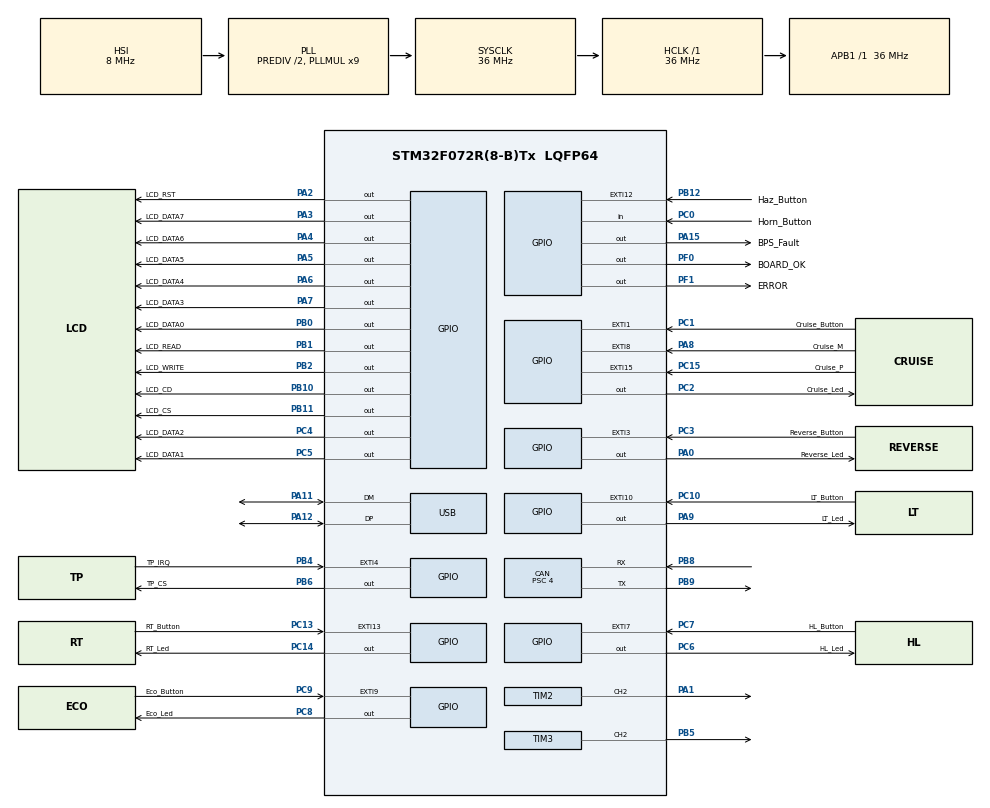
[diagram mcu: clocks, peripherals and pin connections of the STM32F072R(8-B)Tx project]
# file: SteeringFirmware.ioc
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CAN.BS1=CAN_BS1_14TQ
CAN.BS2=CAN_BS2_3TQ
CAN.CalculateBaudRate=500000
CAN.CalculateTimeBit=2000
CAN.CalculateTimeQuantum=111.11111111111111
CAN.Mode=CAN_MODE_NORMAL
CAN.Prescaler=4
CAN.TTCM=DISABLE
FREERTOS.Tasks01=defaultTask,8,128,StartDefaultTask,Default,NULL,Static,defaultTaskBuffer,defaultTaskControlBlock
FREERTOS.configCHECK_FOR_STACK_OVERFLOW=1
FREERTOS.configGENERATE_RUN_TIME_STATS=0
FREERTOS.configTIMER_TASK_PRIORITY=24
FREERTOS.configTIMER_TASK_STACK_DEPTH=256
FREERTOS.configTOTAL_HEAP_SIZE=3072
FREERTOS.configUSE_NEWLIB_REENTRANT=1
Mcu.Family=STM32F0
Mcu.Name=STM32F072R(8-B)Tx
Mcu.Package=LQFP64
NVIC.CEC_CAN_IRQn=true\:3\:0\:false\:false\:true\:true\:true\:true
NVIC.EXTI0_1_IRQn=true\:3\:0\:false\:false\:true\:true\:true\:true
NVIC.EXTI2_3_IRQn=true\:3\:0\:false\:false\:true\:true\:true\:true
NVIC.EXTI4_15_IRQn=true\:3\:0\:false\:false\:true\:true\:true\:true
NVIC.TIM1_BRK_UP_TRG_COM_IRQn=true\:3\:0\:false\:false\:true\:false\:false\:true
NVIC.TimeBase=TIM1_BRK_UP_TRG_COM_IRQn
NVIC.TimeBaseIP=TIM1
PA0.GPIO_Label=Reverse_Led
PA0.Signal=GPIO_Output
PA1.Signal=S_TIM2_CH2
PA11.Mode=Device
PA11.Signal=USB_DM
PA12.Mode=Device
PA12.Signal=USB_DP
PA13.Mode=Serial_Wire
PA13.Signal=SYS_SWDIO
PA14.Mode=Serial_Wire
PA14.Signal=SYS_SWCLK
PA15.GPIO_Label=BPS_Fault
PA15.Signal=GPIO_Output
PA2.GPIO_Label=LCD_RST
PA2.PinState=GPIO_PIN_SET
PA2.Signal=GPIO_Output
PA3.GPIO_Label=LCD_DATA7
PA3.GPIO_Speed=GPIO_SPEED_FREQ_MEDIUM
PA3.Signal=GPIO_Output
PA4.GPIO_Label=LCD_DATA6
PA4.GPIO_Speed=GPIO_SPEED_FREQ_MEDIUM
PA4.Signal=GPIO_Output
PA5.GPIO_Label=LCD_DATA5
PA5.GPIO_Speed=GPIO_SPEED_FREQ_MEDIUM
PA5.Signal=GPIO_Output
PA6.GPIO_Label=LCD_DATA4
PA6.GPIO_Speed=GPIO_SPEED_FREQ_MEDIUM
PA6.Signal=GPIO_Output
PA7.GPIO_Label=LCD_DATA3
PA7.GPIO_Speed=GPIO_SPEED_FREQ_MEDIUM
PA7.Signal=GPIO_Output
PA8.GPIO_Label=Cruise_M
PA8.GPIO_ModeDefaultEXTI=GPIO_MODE_IT_FALLING
PA8.GPIO_PuPd=GPIO_PULLUP
PA8.Signal=GPXTI8
PA9.GPIO_Label=LT_Led
PA9.Signal=GPIO_Output
PB0.GPIO_Label=LCD_DATA0
PB0.GPIO_Speed=GPIO_SPEED_FREQ_MEDIUM
PB0.Signal=GPIO_Output
PB1.GPIO_Label=LCD_READ
PB1.GPIO_Speed=GPIO_SPEED_FREQ_MEDIUM
PB1.PinState=GPIO_PIN_SET
PB1.Signal=GPIO_Output
PB10.GPIO_Label=LCD_CD
PB10.GPIO_Speed=GPIO_SPEED_FREQ_MEDIUM
PB10.PinState=GPIO_PIN_SET
PB10.Signal=GPIO_Output
PB11.GPIO_Label=LCD_CS
PB11.GPIO_Speed=GPIO_SPEED_FREQ_MEDIUM
PB11.PinState=GPIO_PIN_SET
PB11.Signal=GPIO_Output
PB12.GPIO_Label=Haz_Button
PB12.GPIO_ModeDefaultEXTI=GPIO_MODE_IT_FALLING
PB12.GPIO_PuPd=GPIO_PULLUP
PB12.Signal=GPXTI12
PB2.GPIO_Label=LCD_WRITE
PB2.GPIO_Speed=GPIO_SPEED_FREQ_HIGH
PB2.PinState=GPIO_PIN_SET
PB2.Signal=GPIO_Output
PB4.GPIO_Label=TP_IRQ
PB4.Signal=GPXTI4
PB5.Signal=S_TIM3_CH2
PB6.GPIO_Label=TP_CS
PB6.Signal=GPIO_Output
PB8.Mode=CAN_Activate
PB8.Signal=CAN_RX
PB9.Mode=CAN_Activate
PB9.Signal=CAN_TX
PC0.GPIO_Label=Horn_Button
PC0.GPIO_PuPd=GPIO_PULLUP
PC0.Signal=GPIO_Input
PC1.GPIO_Label=Cruise_Button
PC1.GPIO_ModeDefaultEXTI=GPIO_MODE_IT_FALLING
PC1.GPIO_PuPd=GPIO_PULLUP
PC1.Signal=GPXTI1
PC10.GPIO_Label=LT_Button
PC10.GPIO_ModeDefaultEXTI=GPIO_MODE_IT_FALLING
PC10.GPIO_PuPd=GPIO_PULLUP
PC10.Signal=GPXTI10
PC13.GPIO_Label=RT_Button
PC13.GPIO_ModeDefaultEXTI=GPIO_MODE_IT_FALLING
PC13.GPIO_PuPd=GPIO_PULLUP
PC13.Signal=GPXTI13
PC14-OSC32_IN.GPIO_Label=RT_Led
PC14-OSC32_IN.Signal=GPIO_Output
PC15-OSC32_OUT.GPIO_Label=Cruise_P
PC15-OSC32_OUT.GPIO_ModeDefaultEXTI=GPIO_MODE_IT_FALLING
PC15-OSC32_OUT.GPIO_PuPd=GPIO_PULLUP
PC15-OSC32_OUT.Signal=GPXTI15
PC2.GPIO_Label=Cruise_Led
PC2.Signal=GPIO_Output
PC3.GPIO_Label=Reverse_Button
PC3.GPIO_ModeDefaultEXTI=GPIO_MODE_IT_FALLING
PC3.GPIO_PuPd=GPIO_PULLUP
PC3.Signal=GPXTI3
PC4.GPIO_Label=LCD_DATA2
PC4.GPIO_Speed=GPIO_SPEED_FREQ_MEDIUM
PC4.Signal=GPIO_Output
PC5.GPIO_Label=LCD_DATA1
PC5.GPIO_Speed=GPIO_SPEED_FREQ_MEDIUM
PC5.Signal=GPIO_Output
PC6.GPIO_Label=HL_Led
PC6.Signal=GPIO_Output
PC7.GPIO_Label=HL_Button
PC7.GPIO_ModeDefaultEXTI=GPIO_MODE_IT_FALLING
PC7.GPIO_PuPd=GPIO_PULLUP
PC7.Signal=GPXTI7
PC8.GPIO_Label=Eco_Led
PC8.Signal=GPIO_Output
PC9.GPIO_Label=Eco_Button
PC9.GPIO_ModeDefaultEXTI=GPIO_MODE_IT_FALLING
PC9.GPIO_PuPd=GPIO_PULLUP
PC9.Signal=GPXTI9
PF0-OSC_IN.GPIO_Label=BOARD_OK
PF0-OSC_IN.Signal=GPIO_Output
PF1-OSC_OUT.GPIO_Label=ERROR
PF1-OSC_OUT.Signal=GPIO_Output
ProjectManager.HeapSize=0x200
ProjectManager.StackSize=0x400
ProjectManager.TargetToolchain=STM32CubeIDE
RCC.AHBFreq_Value=36000000
RCC.APB1Freq_Value=36000000
RCC.APB1TimFreq_Value=36000000
RCC.HCLKFreq_Value=36000000
RCC.PLLDivider=RCC_PREDIV_DIV2
RCC.PLLMUL=RCC_PLL_MUL9
RCC.SYSCLKFreq_VALUE=36000000
RCC.SYSCLKSource=RCC_SYSCLKSOURCE_PLLCLK
SH.S_TIM2_CH2.0=TIM2_CH2,PWM Generation2 CH2
SH.S_TIM3_CH2.0=TIM3_CH2,PWM Generation2 CH2
TIM2.Channel-PWM\ Generation2\ CH2=TIM_CHANNEL_2
TIM2.Period=2000
TIM2.Prescaler=480
TIM2.Pulse-PWM\ Generation2\ CH2=2000
TIM3.Channel-PWM\ Generation2\ CH2=TIM_CHANNEL_2
TIM3.Period=2000
TIM3.Pulse-PWM\ Generation2\ CH2=1999
VP_FREERTOS_VS_CMSIS_V2.Mode=CMSIS_V2
VP_SYS_VS_tim1.Mode=TIM1
board=custom

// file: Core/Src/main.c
/* USER CODE BEGIN Header */
/**
  ******************************************************************************
  * @file           : main.c
  * @brief          : Main program body
  ******************************************************************************
  * @attention
  *
  * <h2><center>&copy; Copyright (c) 2021 STMicroelectronics.
  * All rights reserved.</center></h2>
  *
  * This software component is licensed by ST under BSD 3-Clause license,
  * the "License"; You may not use this file except in compliance with the
  * License. You may obtain a copy of the License at:
  *                        opensource.org/licenses/BSD-3-Clause
  *
  ******************************************************************************
  */
/* USER CODE END Header */
#include "main.h"
#include "cmsis_os.h"

typedef StaticTask_t osStaticThreadDef_t;

CAN_HandleTypeDef hcan;

TIM_HandleTypeDef htim2;
TIM_HandleTypeDef htim3;

PCD_HandleTypeDef hpcd_USB_FS;

/* Definitions for defaultTask */
osThreadId_t defaultTaskHandle;
uint32_t defaultTaskBuffer[ 128 ];
osStaticThreadDef_t defaultTaskControlBlock;
const osThreadAttr_t defaultTask_attributes = {
  .name = "defaultTask",
  .cb_mem = &defaultTaskControlBlock,
  .cb_size = sizeof(defaultTaskControlBlock),
  .stack_mem = &defaultTaskBuffer[0],
  .stack_size = sizeof(defaultTaskBuffer),
  .priority = (osPriority_t) osPriorityLow,
};

void SystemClock_Config(void);
static void MX_GPIO_Init(void);
static void MX_CAN_Init(void);
static void MX_TIM3_Init(void);
static void MX_TIM2_Init(void);
static void MX_USB_PCD_Init(void);
void StartDefaultTask(void *argument);

/* USER CODE BEGIN PFP */
void CPP_HandleGPIOInterrupt(uint16_t GPIO_Pin);
void CPP_UserSetup(void);
/* USER CODE END PFP */

int main(void)
{

  /* MCU Configuration--------------------------------------------------------*/

  /* Reset of all peripherals, Initializes the Flash interface and the Systick. */
  HAL_Init();

  /* Configure the system clock */
  SystemClock_Config();

  /* Initialize all configured peripherals */
  MX_GPIO_Init();
  MX_CAN_Init();
  MX_TIM3_Init();
  MX_TIM2_Init();
  MX_USB_PCD_Init();

  /* Init scheduler */
  osKernelInitialize();

  /* Create the thread(s) */
  /* creation of defaultTask */
  defaultTaskHandle = osThreadNew(StartDefaultTask, NULL, &defaultTask_attributes);

  /* USER CODE BEGIN RTOS_THREADS */
  CPP_UserSetup();
  /* USER CODE END RTOS_THREADS */

  /* Start scheduler */
  osKernelStart();

  /* We should never get here as control is now taken by the scheduler */
  /* Infinite loop */
  while (1)
  {

  }
}

void SystemClock_Config(void)
{
  RCC_OscInitTypeDef RCC_OscInitStruct = {0};
  RCC_ClkInitTypeDef RCC_ClkInitStruct = {0};
  RCC_PeriphCLKInitTypeDef PeriphClkInit = {0};

  /** Initializes the RCC Oscillators according to the specified parameters
  * in the RCC_OscInitTypeDef structure.
  */
  RCC_OscInitStruct.OscillatorType = RCC_OSCILLATORTYPE_HSI|RCC_OSCILLATORTYPE_HSI48;
  RCC_OscInitStruct.HSIState = RCC_HSI_ON;
  RCC_OscInitStruct.HSI48State = RCC_HSI48_ON;
  RCC_OscInitStruct.HSICalibrationValue = RCC_HSICALIBRATION_DEFAULT;
  RCC_OscInitStruct.PLL.PLLState = RCC_PLL_ON;
  RCC_OscInitStruct.PLL.PLLSource = RCC_PLLSOURCE_HSI;
  RCC_OscInitStruct.PLL.PLLMUL = RCC_PLL_MUL9;
  RCC_OscInitStruct.PLL.PREDIV = RCC_PREDIV_DIV2;
  if (HAL_RCC_OscConfig(&RCC_OscInitStruct) != HAL_OK)
  {
    Error_Handler();
  }
  /** Initializes the CPU, AHB and APB buses clocks
  */
  RCC_ClkInitStruct.ClockType = RCC_CLOCKTYPE_HCLK|RCC_CLOCKTYPE_SYSCLK
                              |RCC_CLOCKTYPE_PCLK1;
  RCC_ClkInitStruct.SYSCLKSource = RCC_SYSCLKSOURCE_PLLCLK;
  RCC_ClkInitStruct.AHBCLKDivider = RCC_SYSCLK_DIV1;
  RCC_ClkInitStruct.APB1CLKDivider = RCC_HCLK_DIV1;

  if (HAL_RCC_ClockConfig(&RCC_ClkInitStruct, FLASH_LATENCY_1) != HAL_OK)
  {
    Error_Handler();
  }
  PeriphClkInit.PeriphClockSelection = RCC_PERIPHCLK_USB;
  PeriphClkInit.UsbClockSelection = RCC_USBCLKSOURCE_HSI48;

  if (HAL_RCCEx_PeriphCLKConfig(&PeriphClkInit) != HAL_OK)
  {
    Error_Handler();
  }
}

static void MX_CAN_Init(void)
{

  hcan.Instance = CAN;
  hcan.Init.Prescaler = 4;
  hcan.Init.Mode = CAN_MODE_NORMAL;
  hcan.Init.SyncJumpWidth = CAN_SJW_1TQ;
  hcan.Init.TimeSeg1 = CAN_BS1_14TQ;
  hcan.Init.TimeSeg2 = CAN_BS2_3TQ;
  hcan.Init.TimeTriggeredMode = DISABLE;
  hcan.Init.AutoBusOff = DISABLE;
  hcan.Init.AutoWakeUp = DISABLE;
  hcan.Init.AutoRetransmission = DISABLE;
  hcan.Init.ReceiveFifoLocked = DISABLE;
  hcan.Init.TransmitFifoPriority = DISABLE;
  if (HAL_CAN_Init(&hcan) != HAL_OK)
  {
    Error_Handler();
  }

}

static void MX_TIM2_Init(void)
{

  TIM_MasterConfigTypeDef sMasterConfig = {0};
  TIM_OC_InitTypeDef sConfigOC = {0};

  htim2.Instance = TIM2;
  htim2.Init.Prescaler = 480;
  htim2.Init.CounterMode = TIM_COUNTERMODE_UP;
  htim2.Init.Period = 2000;
  htim2.Init.ClockDivision = TIM_CLOCKDIVISION_DIV1;
  htim2.Init.AutoReloadPreload = TIM_AUTORELOAD_PRELOAD_DISABLE;
  if (HAL_TIM_PWM_Init(&htim2) != HAL_OK)
  {
    Error_Handler();
  }
  sMasterConfig.MasterOutputTrigger = TIM_TRGO_RESET;
  sMasterConfig.MasterSlaveMode = TIM_MASTERSLAVEMODE_DISABLE;
  if (HAL_TIMEx_MasterConfigSynchronization(&htim2, &sMasterConfig) != HAL_OK)
  {
    Error_Handler();
  }
  sConfigOC.OCMode = TIM_OCMODE_PWM1;
  sConfigOC.Pulse = 2000;
  sConfigOC.OCPolarity = TIM_OCPOLARITY_HIGH;
  sConfigOC.OCFastMode = TIM_OCFAST_DISABLE;
  if (HAL_TIM_PWM_ConfigChannel(&htim2, &sConfigOC, TIM_CHANNEL_2) != HAL_OK)
  {
    Error_Handler();
  }
  HAL_TIM_MspPostInit(&htim2);

}

static void MX_TIM3_Init(void)
{

  TIM_MasterConfigTypeDef sMasterConfig = {0};
  TIM_OC_InitTypeDef sConfigOC = {0};

  htim3.Instance = TIM3;
  htim3.Init.Prescaler = 0;
  htim3.Init.CounterMode = TIM_COUNTERMODE_UP;
  htim3.Init.Period = 2000;
  htim3.Init.ClockDivision = TIM_CLOCKDIVISION_DIV1;
  htim3.Init.AutoReloadPreload = TIM_AUTORELOAD_PRELOAD_DISABLE;
  if (HAL_TIM_PWM_Init(&htim3) != HAL_OK)
  {
    Error_Handler();
  }
  sMasterConfig.MasterOutputTrigger = TIM_TRGO_RESET;
  sMasterConfig.MasterSlaveMode = TIM_MASTERSLAVEMODE_DISABLE;
  if (HAL_TIMEx_MasterConfigSynchronization(&htim3, &sMasterConfig) != HAL_OK)
  {
    Error_Handler();
  }
  sConfigOC.OCMode = TIM_OCMODE_PWM1;
  sConfigOC.Pulse = 1999;
  sConfigOC.OCPolarity = TIM_OCPOLARITY_HIGH;
  sConfigOC.OCFastMode = TIM_OCFAST_DISABLE;
  if (HAL_TIM_PWM_ConfigChannel(&htim3, &sConfigOC, TIM_CHANNEL_2) != HAL_OK)
  {
    Error_Handler();
  }
  HAL_TIM_MspPostInit(&htim3);

}

static void MX_USB_PCD_Init(void)
{

  hpcd_USB_FS.Instance = USB;
  hpcd_USB_FS.Init.dev_endpoints = 8;
  hpcd_USB_FS.Init.speed = PCD_SPEED_FULL;
  hpcd_USB_FS.Init.phy_itface = PCD_PHY_EMBEDDED;
  hpcd_USB_FS.Init.low_power_enable = DISABLE;
  hpcd_USB_FS.Init.lpm_enable = DISABLE;
  hpcd_USB_FS.Init.battery_charging_enable = DISABLE;
  if (HAL_PCD_Init(&hpcd_USB_FS) != HAL_OK)
  {
    Error_Handler();
  }

}

static void MX_GPIO_Init(void)
{
  GPIO_InitTypeDef GPIO_InitStruct = {0};

  /* GPIO Ports Clock Enable */
  __HAL_RCC_GPIOC_CLK_ENABLE();
  __HAL_RCC_GPIOF_CLK_ENABLE();
  __HAL_RCC_GPIOA_CLK_ENABLE();
  __HAL_RCC_GPIOB_CLK_ENABLE();

  /*Configure GPIO pin Output Level */
  HAL_GPIO_WritePin(GPIOC, RT_Led_Pin|Cruise_Led_Pin|LCD_DATA2_Pin|LCD_DATA1_Pin
                          |HL_Led_Pin|Eco_Led_Pin, GPIO_PIN_RESET);

  /*Configure GPIO pin Output Level */
  HAL_GPIO_WritePin(GPIOF, BOARD_OK_Pin|ERROR_Pin, GPIO_PIN_RESET);

  /*Configure GPIO pin Output Level */
  HAL_GPIO_WritePin(GPIOA, Reverse_Led_Pin|LCD_DATA7_Pin|LCD_DATA6_Pin|LCD_DATA5_Pin
                          |LCD_DATA4_Pin|LCD_DATA3_Pin|LT_Led_Pin|BPS_Fault_Pin, GPIO_PIN_RESET);

  /*Configure GPIO pin Output Level */
  HAL_GPIO_WritePin(LCD_RST_GPIO_Port, LCD_RST_Pin, GPIO_PIN_SET);

  /*Configure GPIO pin Output Level */
  HAL_GPIO_WritePin(GPIOB, LCD_DATA0_Pin|TP_CS_Pin, GPIO_PIN_RESET);

  /*Configure GPIO pin Output Level */
  HAL_GPIO_WritePin(GPIOB, LCD_READ_Pin|LCD_WRITE_Pin|LCD_CD_Pin|LCD_CS_Pin, GPIO_PIN_SET);

  /*Configure GPIO pins : RT_Button_Pin Cruise_P_Pin Horn_Button_Pin Cruise_Button_Pin
                           Reverse_Button_Pin HL_Button_Pin Eco_Button_Pin LT_Button_Pin */
  GPIO_InitStruct.Pin = RT_Button_Pin|Cruise_P_Pin|Horn_Button_Pin|Cruise_Button_Pin
                          |Reverse_Button_Pin|HL_Button_Pin|Eco_Button_Pin|LT_Button_Pin;
  GPIO_InitStruct.Mode = GPIO_MODE_IT_FALLING;
  GPIO_InitStruct.Pull = GPIO_PULLUP;
  HAL_GPIO_Init(GPIOC, &GPIO_InitStruct);

  /*Configure GPIO pins : RT_Led_Pin Cruise_Led_Pin HL_Led_Pin Eco_Led_Pin */
  GPIO_InitStruct.Pin = RT_Led_Pin|Cruise_Led_Pin|HL_Led_Pin|Eco_Led_Pin;
  GPIO_InitStruct.Mode = GPIO_MODE_OUTPUT_PP;
  GPIO_InitStruct.Pull = GPIO_NOPULL;
  GPIO_InitStruct.Speed = GPIO_SPEED_FREQ_LOW;
  HAL_GPIO_Init(GPIOC, &GPIO_InitStruct);

  /*Configure GPIO pins : BOARD_OK_Pin ERROR_Pin */
  GPIO_InitStruct.Pin = BOARD_OK_Pin|ERROR_Pin;
  GPIO_InitStruct.Mode = GPIO_MODE_OUTPUT_PP;
  GPIO_InitStruct.Pull = GPIO_NOPULL;
  GPIO_InitStruct.Speed = GPIO_SPEED_FREQ_LOW;
  HAL_GPIO_Init(GPIOF, &GPIO_InitStruct);

  /*Configure GPIO pins : Reverse_Led_Pin LCD_RST_Pin LT_Led_Pin BPS_Fault_Pin */
  GPIO_InitStruct.Pin = Reverse_Led_Pin|LCD_RST_Pin|LT_Led_Pin|BPS_Fault_Pin;
  GPIO_InitStruct.Mode = GPIO_MODE_OUTPUT_PP;
  GPIO_InitStruct.Pull = GPIO_NOPULL;
  GPIO_InitStruct.Speed = GPIO_SPEED_FREQ_LOW;
  HAL_GPIO_Init(GPIOA, &GPIO_InitStruct);

  /*Configure GPIO pins : LCD_DATA7_Pin LCD_DATA6_Pin LCD_DATA5_Pin LCD_DATA4_Pin
                           LCD_DATA3_Pin */
  GPIO_InitStruct.Pin = LCD_DATA7_Pin|LCD_DATA6_Pin|LCD_DATA5_Pin|LCD_DATA4_Pin
                          |LCD_DATA3_Pin;
  GPIO_InitStruct.Mode = GPIO_MODE_OUTPUT_PP;
  GPIO_InitStruct.Pull = GPIO_NOPULL;
  GPIO_InitStruct.Speed = GPIO_SPEED_FREQ_MEDIUM;
  HAL_GPIO_Init(GPIOA, &GPIO_InitStruct);

  /*Configure GPIO pins : LCD_DATA2_Pin LCD_DATA1_Pin */
  GPIO_InitStruct.Pin = LCD_DATA2_Pin|LCD_DATA1_Pin;
  GPIO_InitStruct.Mode = GPIO_MODE_OUTPUT_PP;
  GPIO_InitStruct.Pull = GPIO_NOPULL;
  GPIO_InitStruct.Speed = GPIO_SPEED_FREQ_MEDIUM;
  HAL_GPIO_Init(GPIOC, &GPIO_InitStruct);

  /*Configure GPIO pins : LCD_DATA0_Pin LCD_READ_Pin LCD_CD_Pin LCD_CS_Pin */
  GPIO_InitStruct.Pin = LCD_DATA0_Pin|LCD_READ_Pin|LCD_CD_Pin|LCD_CS_Pin;
  GPIO_InitStruct.Mode = GPIO_MODE_OUTPUT_PP;
  GPIO_InitStruct.Pull = GPIO_NOPULL;
  GPIO_InitStruct.Speed = GPIO_SPEED_FREQ_MEDIUM;
  HAL_GPIO_Init(GPIOB, &GPIO_InitStruct);

  /*Configure GPIO pin : LCD_WRITE_Pin */
  GPIO_InitStruct.Pin = LCD_WRITE_Pin;
  GPIO_InitStruct.Mode = GPIO_MODE_OUTPUT_PP;
  GPIO_InitStruct.Pull = GPIO_NOPULL;
  GPIO_InitStruct.Speed = GPIO_SPEED_FREQ_HIGH;
  HAL_GPIO_Init(LCD_WRITE_GPIO_Port, &GPIO_InitStruct);

  /*Configure GPIO pin : Haz_Button_Pin */
  GPIO_InitStruct.Pin = Haz_Button_Pin;
  GPIO_InitStruct.Mode = GPIO_MODE_IT_FALLING;
  GPIO_InitStruct.Pull = GPIO_PULLUP;
  HAL_GPIO_Init(Haz_Button_GPIO_Port, &GPIO_InitStruct);

  /*Configure GPIO pin : Cruise_M_Pin */
  GPIO_InitStruct.Pin = Cruise_M_Pin;
  GPIO_InitStruct.Mode = GPIO_MODE_IT_FALLING;
  GPIO_InitStruct.Pull = GPIO_PULLUP;
  HAL_GPIO_Init(Cruise_M_GPIO_Port, &GPIO_InitStruct);

  /*Configure GPIO pin : TP_IRQ_Pin */
  GPIO_InitStruct.Pin = TP_IRQ_Pin;
  GPIO_InitStruct.Mode = GPIO_MODE_IT_RISING;
  GPIO_InitStruct.Pull = GPIO_NOPULL;
  HAL_GPIO_Init(TP_IRQ_GPIO_Port, &GPIO_InitStruct);

  /*Configure GPIO pin : TP_CS_Pin */
  GPIO_InitStruct.Pin = TP_CS_Pin;
  GPIO_InitStruct.Mode = GPIO_MODE_OUTPUT_PP;
  GPIO_InitStruct.Pull = GPIO_NOPULL;
  GPIO_InitStruct.Speed = GPIO_SPEED_FREQ_LOW;
  HAL_GPIO_Init(TP_CS_GPIO_Port, &GPIO_InitStruct);

  /* EXTI interrupt init*/
  HAL_NVIC_SetPriority(EXTI0_1_IRQn, 3, 0);
  HAL_NVIC_EnableIRQ(EXTI0_1_IRQn);

  HAL_NVIC_SetPriority(EXTI2_3_IRQn, 3, 0);
  HAL_NVIC_EnableIRQ(EXTI2_3_IRQn);

  HAL_NVIC_SetPriority(EXTI4_15_IRQn, 3, 0);
  HAL_NVIC_EnableIRQ(EXTI4_15_IRQn);

}

/* USER CODE BEGIN 4 */
void HAL_GPIO_EXTI_Callback(uint16_t GPIO_Pin)
{
  // Call into C++ Domain
  CPP_HandleGPIOInterrupt(GPIO_Pin);
}

/* USER CODE END 4 */

void StartDefaultTask(void *argument)
{
  /* USER CODE BEGIN 5 */
  /* Infinite loop */
  for(;;)
  {
    HAL_GPIO_TogglePin(BOARD_OK_GPIO_Port, BOARD_OK_Pin);
    osDelay(500);
  }
  /* USER CODE END 5 */
}

void HAL_TIM_PeriodElapsedCallback(TIM_HandleTypeDef *htim)
{
  if (htim->Instance == TIM1) {
    HAL_IncTick();
  }
}

void Error_Handler(void)
{
  /* USER CODE BEGIN Error_Handler_Debug */
  /* User can add his own implementation to report the HAL error return state */
  __disable_irq();
  while(1)
  {
    HAL_GPIO_TogglePin(ERROR_GPIO_Port, ERROR_Pin);
    osDelay(500);
  }
  /* USER CODE END Error_Handler_Debug */
}

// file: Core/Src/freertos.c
/* USER CODE BEGIN Header */
/**
  ******************************************************************************
  * File Name          : freertos.c
  * Description        : Code for freertos applications
  ******************************************************************************
  * @attention
  *
  * <h2><center>&copy; Copyright (c) 2021 STMicroelectronics.
  * All rights reserved.</center></h2>
  *
  * This software component is licensed by ST under Ultimate Liberty license
  * SLA0044, the "License"; You may not use this file except in compliance with
  * the License. You may obtain a copy of the License at:
  *                             www.st.com/SLA0044
  *
  ******************************************************************************
  */
/* USER CODE END Header */

#include "FreeRTOS.h"
#include "task.h"
#include "main.h"

/* Hook prototypes */
void vApplicationStackOverflowHook(xTaskHandle xTask, signed char *pcTaskName);

/* USER CODE BEGIN 4 */
void vApplicationStackOverflowHook(xTaskHandle xTask, signed char *pcTaskName)
{
   /* Run time stack overflow checking is performed if
   configCHECK_FOR_STACK_OVERFLOW is defined to 1 or 2. This hook function is
   called if a stack overflow is detected. */
  HAL_GPIO_WritePin(ERROR_LED_GPIO_Port, ERROR_LED_Pin, GPIO_PIN_SET);
  while(1)
  { }
}
/* USER CODE END 4 */
